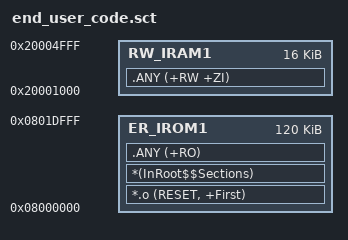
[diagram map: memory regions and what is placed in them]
; *************************************************************
; *** Scatter-Loading Description File generated by uVision ***
; *************************************************************

LR_IROM1 0x08000000 0x0001E000  {    ; load region size_region
  ER_IROM1 0x08000000 0x0001E000  {  ; load address = execution address
   *.o (RESET, +First)
   *(InRoot$$Sections)
   .ANY (+RO)
  }
  RW_IRAM1 0x20001000 0x00004000  {  ; RW data
   .ANY (+RW +ZI)
  }
  
 ; 0x20000000 ~ 0x20000FFF   RAM reserved for SLIB code
 ; 0x0801E000 ~ 0x0801FFFF is SLIB area
}



